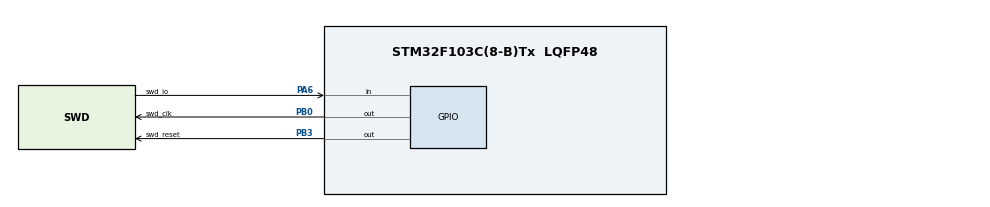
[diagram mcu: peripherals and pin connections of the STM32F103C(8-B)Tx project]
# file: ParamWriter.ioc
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Mcu.Family=STM32F1
Mcu.Name=STM32F103C(8-B)Tx
Mcu.Package=LQFP48
NVIC.PriorityGroup=NVIC_PRIORITYGROUP_4
PA13.Mode=Serial_Wire
PA13.Signal=SYS_JTMS-SWDIO
PA14.Mode=Serial_Wire
PA14.Signal=SYS_JTCK-SWCLK
PA6.GPIO_Label=swd_io
PA6.Signal=GPIO_Input
PB0.GPIO_Label=swd_clk
PB0.PinState=GPIO_PIN_RESET
PB0.Signal=GPIO_Output
PB3.GPIO_Label=swd_reset
PB3.GPIO_ModeDefaultOutputPP=GPIO_MODE_OUTPUT_OD
PB3.GPIO_PuPd=GPIO_NOPULL
PB3.PinState=GPIO_PIN_SET
PB3.Signal=GPIO_Output
PD0-OSC_IN.Mode=HSE-External-Oscillator
PD0-OSC_IN.Signal=RCC_OSC_IN
PD1-OSC_OUT.Mode=HSE-External-Oscillator
PD1-OSC_OUT.Signal=RCC_OSC_OUT
ProjectManager.HeapSize=0x200
ProjectManager.StackSize=0x400
ProjectManager.TargetToolchain=STM32CubeIDE
RCC.AHBFreq_Value=72000000
RCC.APB1CLKDivider=RCC_HCLK_DIV2
RCC.APB1Freq_Value=36000000
RCC.APB1TimFreq_Value=72000000
RCC.APB2Freq_Value=72000000
RCC.APB2TimFreq_Value=72000000
RCC.HCLKFreq_Value=72000000
RCC.PLLMUL=RCC_PLL_MUL9
RCC.PLLSourceVirtual=RCC_PLLSOURCE_HSE
RCC.SYSCLKFreq_VALUE=72000000
RCC.SYSCLKSource=RCC_SYSCLKSOURCE_PLLCLK
RCC.USBFreq_Value=72000000
board=custom

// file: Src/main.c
/* USER CODE BEGIN Header */
/**
  ******************************************************************************
  * @file           : main.c
  * @brief          : Main program body
  ******************************************************************************
  * @attention
  *
  * Copyright (c) 2026 STMicroelectronics.
  * All rights reserved.
  *
  * This software is licensed under terms that can be found in the LICENSE file
  * in the root directory of this software component.
  * If no LICENSE file comes with this software, it is provided AS-IS.
  *
  ******************************************************************************
  */
/* USER CODE END Header */
#include "main.h"

/* USER CODE BEGIN Includes */
#include "../swd/swd.h"
/* USER CODE END Includes */

void SystemClock_Config(void);
static void MX_GPIO_Init(void);

int main(void)
{

  /* MCU Configuration--------------------------------------------------------*/

  /* Reset of all peripherals, Initializes the Flash interface and the Systick. */
  LL_APB2_GRP1_EnableClock(LL_APB2_GRP1_PERIPH_AFIO);
  LL_APB1_GRP1_EnableClock(LL_APB1_GRP1_PERIPH_PWR);

  /* System interrupt init*/
  NVIC_SetPriorityGrouping(NVIC_PRIORITYGROUP_4);

  /* SysTick_IRQn interrupt configuration */
  NVIC_SetPriority(SysTick_IRQn, NVIC_EncodePriority(NVIC_GetPriorityGrouping(),15, 0));

  /** NOJTAG: JTAG-DP Disabled and SW-DP Enabled
  */
  LL_GPIO_AF_Remap_SWJ_NOJTAG();

  /* Configure the system clock */
  SystemClock_Config();

  /* Initialize all configured peripherals */
  MX_GPIO_Init();
  /* USER CODE BEGIN 2 */
  template_init();
  timer_delay_ms(1000);

  //swd_reset_device();
  timer_delay_ms(1000);
  volatile uint8_t start = 0;
  while(start);
  uint32_t idcode;
  swd_init(&idcode);
  swd_set_word_addr(0xE000ED00);
  swd_read_word(&idcode);

  swd_set_word_addr(0x20000028 );
  swd_read_word(&idcode);
  swd_read_word(&idcode);

  uint32_t data[1024];
  swd_err_e err = swd_read_buff(0x08000000, data, 1024);

  /* USER CODE END 2 *
   * /

  /* Infinite loop */
  /* USER CODE BEGIN WHILE */
  while (1)
  {
	  template_cycle();

    /* USER CODE END WHILE */

  }
}

void SystemClock_Config(void)
{
  LL_FLASH_SetLatency(LL_FLASH_LATENCY_2);
  while(LL_FLASH_GetLatency()!= LL_FLASH_LATENCY_2)
  {
  }
  LL_RCC_HSE_Enable();

   /* Wait till HSE is ready */
  while(LL_RCC_HSE_IsReady() != 1)
  {

  }
  LL_RCC_PLL_ConfigDomain_SYS(LL_RCC_PLLSOURCE_HSE_DIV_1, LL_RCC_PLL_MUL_9);
  LL_RCC_PLL_Enable();

   /* Wait till PLL is ready */
  while(LL_RCC_PLL_IsReady() != 1)
  {

  }
  LL_RCC_SetAHBPrescaler(LL_RCC_SYSCLK_DIV_1);
  LL_RCC_SetAPB1Prescaler(LL_RCC_APB1_DIV_2);
  LL_RCC_SetAPB2Prescaler(LL_RCC_APB2_DIV_1);
  LL_RCC_SetSysClkSource(LL_RCC_SYS_CLKSOURCE_PLL);

   /* Wait till System clock is ready */
  while(LL_RCC_GetSysClkSource() != LL_RCC_SYS_CLKSOURCE_STATUS_PLL)
  {

  }
  LL_Init1msTick(72000000);
  LL_SetSystemCoreClock(72000000);
}

static void MX_GPIO_Init(void)
{
  LL_GPIO_InitTypeDef GPIO_InitStruct = {0};

  /* GPIO Ports Clock Enable */
  LL_APB2_GRP1_EnableClock(LL_APB2_GRP1_PERIPH_GPIOD);
  LL_APB2_GRP1_EnableClock(LL_APB2_GRP1_PERIPH_GPIOA);
  LL_APB2_GRP1_EnableClock(LL_APB2_GRP1_PERIPH_GPIOB);

  /**/
  LL_GPIO_ResetOutputPin(swd_clk_GPIO_Port, swd_clk_Pin);

  /**/
  LL_GPIO_SetOutputPin(swd_reset_GPIO_Port, swd_reset_Pin);

  /**/
  GPIO_InitStruct.Pin = swd_io_Pin;
  GPIO_InitStruct.Mode = LL_GPIO_MODE_FLOATING;
  LL_GPIO_Init(swd_io_GPIO_Port, &GPIO_InitStruct);

  /**/
  GPIO_InitStruct.Pin = swd_clk_Pin;
  GPIO_InitStruct.Mode = LL_GPIO_MODE_OUTPUT;
  GPIO_InitStruct.Speed = LL_GPIO_SPEED_FREQ_LOW;
  GPIO_InitStruct.OutputType = LL_GPIO_OUTPUT_PUSHPULL;
  LL_GPIO_Init(swd_clk_GPIO_Port, &GPIO_InitStruct);

  /**/
  GPIO_InitStruct.Pin = swd_reset_Pin;
  GPIO_InitStruct.Mode = LL_GPIO_MODE_OUTPUT;
  GPIO_InitStruct.Speed = LL_GPIO_SPEED_FREQ_LOW;
  GPIO_InitStruct.OutputType = LL_GPIO_OUTPUT_OPENDRAIN;
  LL_GPIO_Init(swd_reset_GPIO_Port, &GPIO_InitStruct);

}

void Error_Handler(void)
{
  __disable_irq();
  while (1)
  {
  }
}
